AUTOSAR XML (schema 4-1-3)
standard types defined: boolean, uint32, uint8
package /UAES/ASW/CompuMethods
  compu method CM_boolean: 0=FALSE, 1=TRUE
package /UAES/ASW/DataConstrs
  range DC_boolean: raw 0..1
  range DC_uint32: raw 0..4294967295
  range DC_uint8: raw 0..255
package /UAES/ASW/DataTypeMappingSets
  data type mapping set EFuse_Ctrl
package /UAES/ASW/ImplementationDataTypes
  impl type rt_Array_uint32_9: category=ARRAY, sw-calibration-access=READ-ONLY, type-emitter=RTE
    element rt_Array_uint32_9: array-size=9, array-size-semantics=FIXED-SIZE, implementation-data-type=uint32
  impl type rt_Array_uint8_9: category=ARRAY, sw-calibration-access=READ-ONLY, type-emitter=RTE
    element rt_Array_uint8_9: array-size=9, array-size-semantics=FIXED-SIZE, implementation-data-type=uint8
package /UAES/ASW/PortInterfaces
  7 x sender receiver interface:
    EFuse_ActUseFuseChInfo: invalidation-policy{data-element=EFuse_ActUseFuseChInfo/Val, handle-invalid=DONT-INVALIDATE}
      data Val: sw-calibration-access=READ-ONLY, type=uint32
    EFuse_au32ErrInfo: invalidation-policy{data-element=EFuse_au32ErrInfo/Val, handle-invalid=DONT-INVALIDATE}
      data Val: sw-calibration-access=READ-ONLY, type=rt_Array_uint32_9
    EFuse_au8stFuse: invalidation-policy{data-element=EFuse_au8stFuse/Val, handle-invalid=DONT-INVALIDATE}
      data Val: sw-calibration-access=READ-ONLY, type=rt_Array_uint8_9
    EFuse_au8stSleep: invalidation-policy{data-element=EFuse_au8stSleep/Val, handle-invalid=DONT-INVALIDATE}
      data Val: sw-calibration-access=READ-ONLY, type=rt_Array_uint8_9
    EFuse_flgAllwSleep: invalidation-policy{data-element=EFuse_flgAllwSleep/Val, handle-invalid=DONT-INVALIDATE}
      data Val: sw-calibration-access=READ-ONLY, type=boolean
    EFuse_flgPreSleep: invalidation-policy{data-element=EFuse_flgPreSleep/Val, handle-invalid=DONT-INVALIDATE}
      data Val: sw-calibration-access=READ-ONLY, type=boolean
    EFuse_flgPwrModChng: invalidation-policy{data-element=EFuse_flgPwrModChng/Val, handle-invalid=DONT-INVALIDATE}
      data Val: sw-calibration-access=READ-ONLY, type=boolean
package /UAES/ASW/SwAddrMethods
  sw addr method CALDATA
package /UAES/ASW/SwComponentTypes
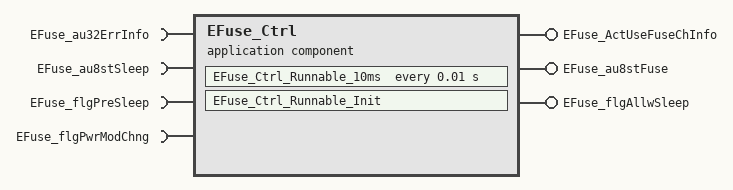
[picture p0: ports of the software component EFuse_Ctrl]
  application sw component type EFuse_Ctrl
    provide port EFuse_ActUseFuseChInfo: nonqueued-sender-com-spec{data-element=EFuse_ActUseFuseChInfo/Val, init-value=0}, provided-interface=EFuse_ActUseFuseChInfo
    provide port EFuse_au8stFuse: nonqueued-sender-com-spec{data-element=EFuse_au8stFuse/Val, init-value=9 x 0}, provided-interface=EFuse_au8stFuse
    provide port EFuse_flgAllwSleep: nonqueued-sender-com-spec{data-element=EFuse_flgAllwSleep/Val, init-value=0}, provided-interface=EFuse_flgAllwSleep
    4 x require port:
      EFuse_au32ErrInfo: nonqueued-receiver-com-spec{data-element=EFuse_au32ErrInfo/Val, filter=data-filter-type=ALWAYS, init-value=9 x 0}, required-interface=EFuse_au32ErrInfo
      EFuse_au8stSleep: nonqueued-receiver-com-spec{data-element=EFuse_au8stSleep/Val, filter=data-filter-type=ALWAYS, init-value=9 x 0}, required-interface=EFuse_au8stSleep
      EFuse_flgPreSleep: nonqueued-receiver-com-spec{data-element=EFuse_flgPreSleep/Val, filter=data-filter-type=ALWAYS, init-value=0}, required-interface=EFuse_flgPreSleep
      EFuse_flgPwrModChng: nonqueued-receiver-com-spec{data-element=EFuse_flgPwrModChng/Val, filter=data-filter-type=ALWAYS, init-value=0}, required-interface=EFuse_flgPwrModChng
    behavior EFuse_Ctrl_InternalBehavior: data-type-mapping=EFuse_Ctrl
      timing event TMT_EFuse_PowSplyCtl_Runnable_10ms: start-on-event=EFuse_Ctrl_Runnable_10ms, period=0.01
      init event EFuse_PowSplyCtl_Runnable_InitEvent: start-on-event=EFuse_Ctrl_Runnable_Init
      runnable EFuse_Ctrl_Runnable_10ms
        data-read-access:
          4 x access:
            READ_EFuse_au32ErrInfo_Val: accessed-variable=EFuse_au32ErrInfo.Val
            READ_EFuse_au8stSleep_Val: accessed-variable=EFuse_au8stSleep.Val
            READ_EFuse_flgPreSleep_Val: accessed-variable=EFuse_flgPreSleep.Val
            READ_EFuse_flgPwrModChng_Val: accessed-variable=EFuse_flgPwrModChng.Val
        data-write-access:
          access WRITE_EFuse_ActUseFuseChInfo_Val: accessed-variable=EFuse_ActUseFuseChInfo.Val
          access WRITE_EFuse_au8stFuse_Val: accessed-variable=EFuse_au8stFuse.Val
          access WRITE_EFuse_flgAllwSleep_Val: accessed-variable=EFuse_flgAllwSleep.Val
        7 x parameter access:
          PA_EFuse_ActUseFuseChInfo_C: accessed-parameter=EFuse_ActUseFuseChInfo_C
          PA_EFuse_EnSleepFailRetry_C: accessed-parameter=EFuse_EnSleepFailRetry_C
          PA_EFuse_nSleepFailMax_C: accessed-parameter=EFuse_nSleepFailMax_C
          PA_EFuse_ReWrkSel_C: accessed-parameter=EFuse_ReWrkSel_C
          PA_EFuse_SWPrtSel_C: accessed-parameter=EFuse_SWPrtSel_C
          PA_EFuse_tiSleepFailRetry_C: accessed-parameter=EFuse_tiSleepFailRetry_C
          PA_EFuse_tiSleepFailToNrm_C: accessed-parameter=EFuse_tiSleepFailToNrm_C
      runnable EFuse_Ctrl_Runnable_Init
        7 x parameter access:
          PA_EFuse_ActUseFuseChInfo_C: accessed-parameter=EFuse_ActUseFuseChInfo_C
          PA_EFuse_EnSleepFailRetry_C: accessed-parameter=EFuse_EnSleepFailRetry_C
          PA_EFuse_nSleepFailMax_C: accessed-parameter=EFuse_nSleepFailMax_C
          PA_EFuse_ReWrkSel_C: accessed-parameter=EFuse_ReWrkSel_C
          PA_EFuse_SWPrtSel_C: accessed-parameter=EFuse_SWPrtSel_C
          PA_EFuse_tiSleepFailRetry_C: accessed-parameter=EFuse_tiSleepFailRetry_C
          PA_EFuse_tiSleepFailToNrm_C: accessed-parameter=EFuse_tiSleepFailToNrm_C
      shared-parameters:
        7 x parameter data prototype, all with sw-addr-method=CALDATA, sw-calibration-access=READ-WRITE:
          EFuse_ActUseFuseChInfo_C: type=uint32, init-value=54
          EFuse_EnSleepFailRetry_C: type=boolean, init-value=1
          EFuse_nSleepFailMax_C: type=uint8, init-value=3
          EFuse_ReWrkSel_C: type=uint8, init-value=1
          EFuse_SWPrtSel_C: type=uint8, init-value=15
          EFuse_tiSleepFailRetry_C: type=uint32, init-value=2000
          EFuse_tiSleepFailToNrm_C: type=uint32, init-value=2000
  swc implementation EFuse_Ctrl_Implementation: behavior=EFuse_Ctrl_InternalBehavior
    code-descriptors:
      code Default: artifact-descriptors=autosar-engineering-object={short-label=Default, category=SWSRC}
package /UAES/ASW/Units
  unit NoUnit: factor-si-to-unit=1, offset-si-to-unit=0
